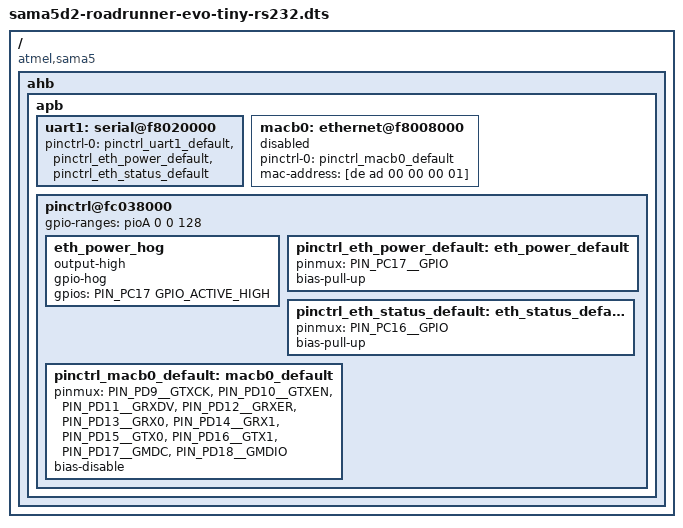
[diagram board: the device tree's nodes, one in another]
/dts-v1/;
/plugin/;

#include "../sama5d2-pinfunc.h"
#include <dt-bindings/gpio/gpio.h>
#include <dt-bindings/mfd/atmel-flexcom.h>

/ {
    fragment@111111_rs232 {
        target-path = "/";
        __overlay__ {
            compatible = "atmel,sama5", "atmel,sama5d2", "atmel,sama5d2-evo-tiny-rs232";
            ahb {
                apb {
                    uart1: serial@f8020000 {
                        pinctrl-names = "default";
                        /* pinctrl-0 = <&pinctrl_uart1_default>; */
                        pinctrl-0 = <&pinctrl_uart1_default
                                     &pinctrl_eth_power_default
                                     &pinctrl_eth_status_default>;
                        status = "okay";
                    };

                    macb0: ethernet@f8008000 {
                        pinctrl-names = "default";
                        pinctrl-0 = <&pinctrl_macb0_default>;
                        status = "disabled";
                        mac-address = [de ad 00 00 00 01];
                    };

                    pinctrl@fc038000 {
                        gpio-ranges = <&pioA 0 0 128>;

                        eth_power_hog {
                            output-high;
                            gpio-hog;
                            gpios = <PIN_PC17 GPIO_ACTIVE_HIGH>;
                        };

                        pinctrl_eth_power_default: eth_power_default {
                            pinmux  = <PIN_PC17__GPIO>;
                            bias-pull-up;
                        };

                        pinctrl_eth_status_default: eth_status_default {
                            pinmux  = <PIN_PC16__GPIO>;
                            bias-pull-up;
                        };

                        pinctrl_macb0_default: macb0_default {
                            pinmux = <PIN_PD9__GTXCK>,
                                     <PIN_PD10__GTXEN>,
                                     <PIN_PD11__GRXDV>,
                                     <PIN_PD12__GRXER>,
                                     <PIN_PD13__GRX0>,
                                     <PIN_PD14__GRX1>,
                                     <PIN_PD15__GTX0>,
                                     <PIN_PD16__GTX1>,
                                     <PIN_PD17__GMDC>,
                                     <PIN_PD18__GMDIO>;
                            bias-disable;
                        };

                        /*
                        pinctrl_macb0_phy_irq: macb0_phy_irq {
                            pinmux = <PIN_PC9__GPIO>;
                            bias-disable;
                        };
                        */
                    };
                };
            };
        };
    };
};
